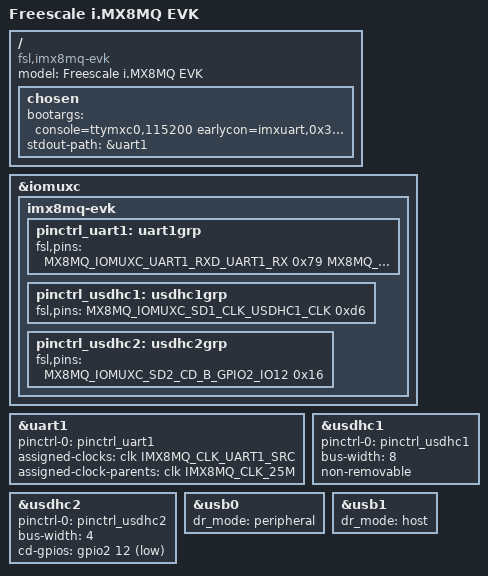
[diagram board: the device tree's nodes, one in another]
/*
 * Copyright (C) 2016 Freescale Semiconductor, Inc.
 * Copyright 2017 NXP
 *
 * This program is free software; you can redistribute it and/or
 * modify it under the terms of the GNU General Public License
 * as published by the Free Software Foundation; either version 2
 * of the License, or (at your option) any later version.
 *
 * This program is distributed in the hope that it will be useful,
 * but WITHOUT ANY WARRANTY; without even the implied warranty of
 * MERCHANTABILITY or FITNESS FOR A PARTICULAR PURPOSE.  See the
 * GNU General Public License for more details.
 */

/dts-v1/;

/* First 128KB is for PSCI ATF. */
/memreserve/ 0x40000000 0x00020000;

#include "fsl-imx8mq.dtsi"

/ {
	model = "Freescale i.MX8MQ EVK";
	compatible = "fsl,imx8mq-evk", "fsl,imx8mq";

	chosen {
		bootargs = "console=ttymxc0,115200 earlycon=imxuart,0x30860000,115200";
		stdout-path = &uart1;
	};
};

&iomuxc {
	pinctrl-names = "default";

	imx8mq-evk {

		pinctrl_uart1: uart1grp {
			fsl,pins = <
				MX8MQ_IOMUXC_UART1_RXD_UART1_RX		0x79
				MX8MQ_IOMUXC_UART1_TXD_UART1_TX		0x79
			>;
		};

		pinctrl_usdhc1: usdhc1grp {
			fsl,pins = <
				MX8MQ_IOMUXC_SD1_CLK_USDHC1_CLK		0xd6
			>;
		};

		pinctrl_usdhc2: usdhc2grp {
			fsl,pins = <
				MX8MQ_IOMUXC_SD2_CD_B_GPIO2_IO12	0x16
			>;
		};
	};
};

&uart1 {
	pinctrl-names = "default";
	pinctrl-0 = <&pinctrl_uart1>;
	assigned-clocks = <&clk IMX8MQ_CLK_UART1_SRC>;
	assigned-clock-parents = <&clk IMX8MQ_CLK_25M>;
	status = "okay";
};

&usdhc1 {
	pinctrl-names = "default";
	pinctrl-0 = <&pinctrl_usdhc1>;
	bus-width = <8>;
	non-removable;
	status = "okay";
};

&usdhc2 {
	pinctrl-names = "default";
	pinctrl-0 = <&pinctrl_usdhc2>;
	bus-width = <4>;
	cd-gpios = <&gpio2 12 GPIO_ACTIVE_LOW>;
	status = "okay";
};

&usb0 {
	dr_mode = "peripheral";
	status = "okay";
};

&usb1 {
	dr_mode = "host";
	status = "okay";
};
